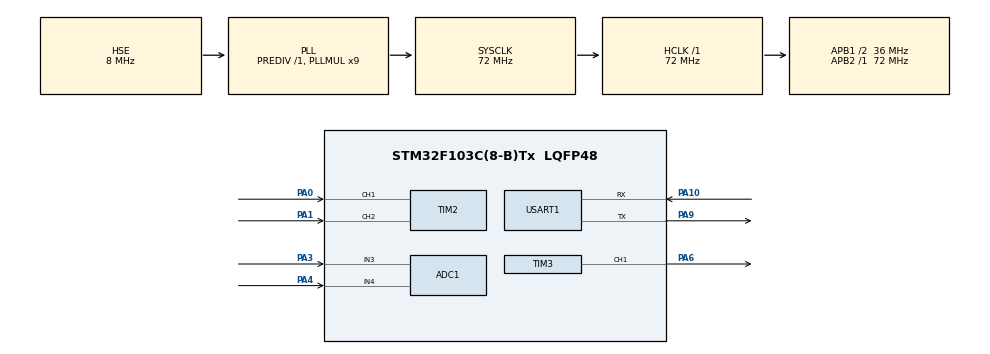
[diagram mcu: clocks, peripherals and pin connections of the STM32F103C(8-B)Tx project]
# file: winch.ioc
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ADC1.Channel-0\#ChannelRegularConversion=ADC_CHANNEL_3
ADC1.Channel-1\#ChannelRegularConversion=ADC_CHANNEL_3
ADC1.ContinuousConvMode=DISABLE
ADC1.DiscontinuousConvMode=ENABLE
ADC1.NbrOfConversion=2
ADC1.NbrOfConversionFlag=1
ADC1.Rank-0\#ChannelRegularConversion=1
ADC1.Rank-1\#ChannelRegularConversion=2
ADC1.SamplingTime-0\#ChannelRegularConversion=ADC_SAMPLETIME_1CYCLE_5
ADC1.SamplingTime-1\#ChannelRegularConversion=ADC_SAMPLETIME_1CYCLE_5
ADC1.master=1
Dma.ADC1.0.Direction=DMA_PERIPH_TO_MEMORY
Dma.ADC1.0.Instance=DMA1_Channel1
Dma.ADC1.0.MemDataAlignment=DMA_MDATAALIGN_WORD
Dma.ADC1.0.MemInc=DMA_MINC_ENABLE
Dma.ADC1.0.Mode=DMA_CIRCULAR
Dma.ADC1.0.PeriphDataAlignment=DMA_PDATAALIGN_WORD
Dma.ADC1.0.PeriphInc=DMA_PINC_DISABLE
Dma.ADC1.0.Priority=DMA_PRIORITY_VERY_HIGH
Dma.Request0=ADC1
Mcu.Family=STM32F1
Mcu.Name=STM32F103C(8-B)Tx
Mcu.Package=LQFP48
NVIC.DMA1_Channel1_IRQn=true\:0\:0\:false\:false\:true\:false\:true
NVIC.PriorityGroup=NVIC_PRIORITYGROUP_4
PA0-WKUP.Signal=S_TIM2_CH1_ETR
PA1.Signal=S_TIM2_CH2
PA10.Mode=Asynchronous
PA10.Signal=USART1_RX
PA13.Mode=Serial_Wire
PA13.Signal=SYS_JTMS-SWDIO
PA14.Mode=Serial_Wire
PA14.Signal=SYS_JTCK-SWCLK
PA3.Signal=ADCx_IN3
PA4.Signal=ADCx_IN4
PA6.Signal=S_TIM3_CH1
PA9.Mode=Asynchronous
PA9.Signal=USART1_TX
PD0-OSC_IN.Mode=HSE-External-Oscillator
PD0-OSC_IN.Signal=RCC_OSC_IN
PD1-OSC_OUT.Mode=HSE-External-Oscillator
PD1-OSC_OUT.Signal=RCC_OSC_OUT
ProjectManager.HeapSize=0x200
ProjectManager.StackSize=0x400
ProjectManager.TargetToolchain=STM32CubeIDE
RCC.ADCPresc=RCC_ADCPCLK2_DIV6
RCC.AHBFreq_Value=72000000
RCC.APB1CLKDivider=RCC_HCLK_DIV2
RCC.APB1Freq_Value=36000000
RCC.APB1TimFreq_Value=72000000
RCC.APB2Freq_Value=72000000
RCC.APB2TimFreq_Value=72000000
RCC.HCLKFreq_Value=72000000
RCC.PLLMUL=RCC_PLL_MUL9
RCC.PLLSourceVirtual=RCC_PLLSOURCE_HSE
RCC.SYSCLKFreq_VALUE=72000000
RCC.SYSCLKSource=RCC_SYSCLKSOURCE_PLLCLK
RCC.USBFreq_Value=72000000
SH.ADCx_IN3.0=ADC1_IN3,IN3
SH.ADCx_IN4.0=ADC1_IN4,IN4
SH.S_TIM2_CH1_ETR.0=TIM2_CH1,Encoder_Interface
SH.S_TIM2_CH2.0=TIM2_CH2,Encoder_Interface
SH.S_TIM3_CH1.0=TIM3_CH1,PWM Generation1 CH1
TIM2.AutoReloadPreload=TIM_AUTORELOAD_PRELOAD_ENABLE
TIM2.EncoderMode=TIM_ENCODERMODE_TI12
TIM2.IC1Filter=10
TIM2.IC2Filter=10
TIM3.AutoReloadPreload=TIM_AUTORELOAD_PRELOAD_ENABLE
TIM3.Channel-PWM\ Generation1\ CH1=TIM_CHANNEL_1
TIM3.OC1Preload_PWM=DISABLE
TIM3.OCFastMode_PWM-PWM\ Generation1\ CH1=TIM_OCFAST_ENABLE
USART1.VirtualMode=VM_ASYNC
VP_TIM3_VS_ClockSourceINT.Mode=Internal
board=custom

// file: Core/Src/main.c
/* USER CODE BEGIN Header */
/**
 ******************************************************************************
 * @file           : main.c
 * @brief          : Main program body
 ******************************************************************************
 * @attention
 *
 * Copyright (c) 2023 STMicroelectronics.
 * All rights reserved.
 *
 * This software is licensed under terms that can be found in the LICENSE file
 * in the root directory of this software component.
 * If no LICENSE file comes with this software, it is provided AS-IS.
 *
 ******************************************************************************
 */
/* USER CODE END Header */
#include "main.h"

/* USER CODE BEGIN Includes */
#define MAX_Tension 300
#define IDEAL_Tension 30
/* USER CODE END Includes */

/* USER CODE BEGIN PTD */
volatile uint32_t tim1_cnt=0,direction,rise=0;

uint32_t adc_val = 0;
uint32_t buffer;
uint8_t MSG[50] = {'\0'};
//float sensitivity = 0.1; // 0.1 for 20A Model
float rawVoltage;
float current;
long val;
/* USER CODE END PTD */

ADC_HandleTypeDef hadc1;
DMA_HandleTypeDef hdma_adc1;

TIM_HandleTypeDef htim2;
TIM_HandleTypeDef htim3;

UART_HandleTypeDef huart1;

void SystemClock_Config(void);
static void MX_GPIO_Init(void);
static void MX_ADC1_Init(void);
static void MX_TIM2_Init(void);
static void MX_DMA_Init(void);
static void MX_USART1_UART_Init(void);
static void MX_TIM3_Init(void);

long map(long x, long in_min, long in_max, long out_min, long out_max)
{
  return (x - in_min) * (out_max - out_min) / (in_max - in_min) + out_min;
}

int main(void)
{

  /* MCU Configuration--------------------------------------------------------*/

  /* Reset of all peripherals, Initializes the Flash interface and the Systick. */
  HAL_Init();

  /* Configure the system clock */
  SystemClock_Config();

  /* Initialize all configured peripherals */
  MX_GPIO_Init();
  MX_ADC1_Init();
  MX_TIM2_Init();
  MX_DMA_Init();
  MX_USART1_UART_Init();
  MX_TIM3_Init();
  /* USER CODE BEGIN 2 */
	HAL_TIM_Encoder_Start(&htim2, TIM_CHANNEL_ALL);
	//HAL_ADC_Start_DMA(&hadc1, &buffer, 1);
	HAL_TIM_PWM_Start(&htim3, TIM_CHANNEL_1);
  /* USER CODE END 2 */

  /* Infinite loop */
  /* USER CODE BEGIN WHILE  ((TIM2->CNT)>>2)*/
	while (1) {
    /* USER CODE END WHILE */
//		tim1_cnt = __HAL_TIM_GET_COUNTER(&htim2);
		HAL_TIM_PeriodElapsedCallback(&htim2);
			direction = !(__HAL_TIM_IS_TIM_COUNTING_DOWN(&htim2));
			sprintf(MSG, "	Ticks = %d, adc=%d ,Current=%f\n", ((TIM2->CNT)>>2),(int)val,current);
			            HAL_UART_Transmit(&huart1, MSG, sizeof(MSG), 10);
			/*if(current>MAX_Tension || current ==0.0)
			{
				while(current > IDEAL_Tension || current==0.0)
				{
					TIM3->CCR1 = 80;

				}
			}*/
	}
}

void HAL_TIM_PeriodElapsedCallback(TIM_HandleTypeDef *htim)

{
	//tim1_cnt = __HAL_TIM_GET_COUNTER(&htim2);

   if (htim -> Instance == TIM2)

   {

   HAL_ADC_Start_DMA(&hadc1, &buffer, 10);

   }

}

void HAL_ADC_ConvCpltCallback(ADC_HandleTypeDef* hadc)
{
   adc_val = buffer;
   val=map(adc_val, 0, 255,0 , 4095);
   rawVoltage = (float) val * 3.3 * 2 / 4095;
       // If rawVoltage is not 2.5Volt, multiply by a factor.In my case it is 1.035
       // This is due to tolerance in voltage divider resister & ADC accuracy
       current =((rawVoltage - 2.503)/0.185)*1000;
   HAL_ADC_Stop_DMA(&hadc1);
}
void SystemClock_Config(void)
{
  RCC_OscInitTypeDef RCC_OscInitStruct = {0};
  RCC_ClkInitTypeDef RCC_ClkInitStruct = {0};
  RCC_PeriphCLKInitTypeDef PeriphClkInit = {0};

  /** Initializes the RCC Oscillators according to the specified parameters
  * in the RCC_OscInitTypeDef structure.
  */
  RCC_OscInitStruct.OscillatorType = RCC_OSCILLATORTYPE_HSE;
  RCC_OscInitStruct.HSEState = RCC_HSE_ON;
  RCC_OscInitStruct.HSEPredivValue = RCC_HSE_PREDIV_DIV1;
  RCC_OscInitStruct.HSIState = RCC_HSI_ON;
  RCC_OscInitStruct.PLL.PLLState = RCC_PLL_ON;
  RCC_OscInitStruct.PLL.PLLSource = RCC_PLLSOURCE_HSE;
  RCC_OscInitStruct.PLL.PLLMUL = RCC_PLL_MUL9;
  if (HAL_RCC_OscConfig(&RCC_OscInitStruct) != HAL_OK)
  {
    Error_Handler();
  }
  /** Initializes the CPU, AHB and APB buses clocks
  */
  RCC_ClkInitStruct.ClockType = RCC_CLOCKTYPE_HCLK|RCC_CLOCKTYPE_SYSCLK
                              |RCC_CLOCKTYPE_PCLK1|RCC_CLOCKTYPE_PCLK2;
  RCC_ClkInitStruct.SYSCLKSource = RCC_SYSCLKSOURCE_PLLCLK;
  RCC_ClkInitStruct.AHBCLKDivider = RCC_SYSCLK_DIV1;
  RCC_ClkInitStruct.APB1CLKDivider = RCC_HCLK_DIV2;
  RCC_ClkInitStruct.APB2CLKDivider = RCC_HCLK_DIV1;

  if (HAL_RCC_ClockConfig(&RCC_ClkInitStruct, FLASH_LATENCY_2) != HAL_OK)
  {
    Error_Handler();
  }
  PeriphClkInit.PeriphClockSelection = RCC_PERIPHCLK_ADC;
  PeriphClkInit.AdcClockSelection = RCC_ADCPCLK2_DIV6;
  if (HAL_RCCEx_PeriphCLKConfig(&PeriphClkInit) != HAL_OK)
  {
    Error_Handler();
  }
}

static void MX_ADC1_Init(void)
{

  ADC_ChannelConfTypeDef sConfig = {0};

  /** Common config
  */
  hadc1.Instance = ADC1;
  hadc1.Init.ScanConvMode = ADC_SCAN_ENABLE;
  hadc1.Init.ContinuousConvMode = DISABLE;
  hadc1.Init.DiscontinuousConvMode = ENABLE;
  hadc1.Init.NbrOfDiscConversion = 1;
  hadc1.Init.ExternalTrigConv = ADC_SOFTWARE_START;
  hadc1.Init.DataAlign = ADC_DATAALIGN_RIGHT;
  hadc1.Init.NbrOfConversion = 2;
  if (HAL_ADC_Init(&hadc1) != HAL_OK)
  {
    Error_Handler();
  }
  /** Configure Regular Channel
  */
  sConfig.Channel = ADC_CHANNEL_3;
  sConfig.Rank = ADC_REGULAR_RANK_1;
  sConfig.SamplingTime = ADC_SAMPLETIME_1CYCLE_5;
  if (HAL_ADC_ConfigChannel(&hadc1, &sConfig) != HAL_OK)
  {
    Error_Handler();
  }
  /** Configure Regular Channel
  */
  sConfig.Rank = ADC_REGULAR_RANK_2;
  if (HAL_ADC_ConfigChannel(&hadc1, &sConfig) != HAL_OK)
  {
    Error_Handler();
  }

}

static void MX_TIM2_Init(void)
{

  TIM_Encoder_InitTypeDef sConfig = {0};
  TIM_MasterConfigTypeDef sMasterConfig = {0};

  htim2.Instance = TIM2;
  htim2.Init.Prescaler = 0;
  htim2.Init.CounterMode = TIM_COUNTERMODE_UP;
  htim2.Init.Period = 65535;
  htim2.Init.ClockDivision = TIM_CLOCKDIVISION_DIV1;
  htim2.Init.AutoReloadPreload = TIM_AUTORELOAD_PRELOAD_ENABLE;
  sConfig.EncoderMode = TIM_ENCODERMODE_TI12;
  sConfig.IC1Polarity = TIM_ICPOLARITY_RISING;
  sConfig.IC1Selection = TIM_ICSELECTION_DIRECTTI;
  sConfig.IC1Prescaler = TIM_ICPSC_DIV1;
  sConfig.IC1Filter = 10;
  sConfig.IC2Polarity = TIM_ICPOLARITY_RISING;
  sConfig.IC2Selection = TIM_ICSELECTION_DIRECTTI;
  sConfig.IC2Prescaler = TIM_ICPSC_DIV1;
  sConfig.IC2Filter = 10;
  if (HAL_TIM_Encoder_Init(&htim2, &sConfig) != HAL_OK)
  {
    Error_Handler();
  }
  sMasterConfig.MasterOutputTrigger = TIM_TRGO_RESET;
  sMasterConfig.MasterSlaveMode = TIM_MASTERSLAVEMODE_DISABLE;
  if (HAL_TIMEx_MasterConfigSynchronization(&htim2, &sMasterConfig) != HAL_OK)
  {
    Error_Handler();
  }

}

static void MX_TIM3_Init(void)
{

  TIM_ClockConfigTypeDef sClockSourceConfig = {0};
  TIM_MasterConfigTypeDef sMasterConfig = {0};
  TIM_OC_InitTypeDef sConfigOC = {0};

  htim3.Instance = TIM3;
  htim3.Init.Prescaler = 0;
  htim3.Init.CounterMode = TIM_COUNTERMODE_UP;
  htim3.Init.Period = 65535;
  htim3.Init.ClockDivision = TIM_CLOCKDIVISION_DIV1;
  htim3.Init.AutoReloadPreload = TIM_AUTORELOAD_PRELOAD_ENABLE;
  if (HAL_TIM_Base_Init(&htim3) != HAL_OK)
  {
    Error_Handler();
  }
  sClockSourceConfig.ClockSource = TIM_CLOCKSOURCE_INTERNAL;
  if (HAL_TIM_ConfigClockSource(&htim3, &sClockSourceConfig) != HAL_OK)
  {
    Error_Handler();
  }
  if (HAL_TIM_PWM_Init(&htim3) != HAL_OK)
  {
    Error_Handler();
  }
  sMasterConfig.MasterOutputTrigger = TIM_TRGO_RESET;
  sMasterConfig.MasterSlaveMode = TIM_MASTERSLAVEMODE_DISABLE;
  if (HAL_TIMEx_MasterConfigSynchronization(&htim3, &sMasterConfig) != HAL_OK)
  {
    Error_Handler();
  }
  sConfigOC.OCMode = TIM_OCMODE_PWM1;
  sConfigOC.Pulse = 0;
  sConfigOC.OCPolarity = TIM_OCPOLARITY_HIGH;
  sConfigOC.OCFastMode = TIM_OCFAST_DISABLE;
  if (HAL_TIM_PWM_ConfigChannel(&htim3, &sConfigOC, TIM_CHANNEL_1) != HAL_OK)
  {
    Error_Handler();
  }
  HAL_TIM_MspPostInit(&htim3);

}

static void MX_USART1_UART_Init(void)
{

  huart1.Instance = USART1;
  huart1.Init.BaudRate = 115200;
  huart1.Init.WordLength = UART_WORDLENGTH_8B;
  huart1.Init.StopBits = UART_STOPBITS_1;
  huart1.Init.Parity = UART_PARITY_NONE;
  huart1.Init.Mode = UART_MODE_TX_RX;
  huart1.Init.HwFlowCtl = UART_HWCONTROL_NONE;
  huart1.Init.OverSampling = UART_OVERSAMPLING_16;
  if (HAL_UART_Init(&huart1) != HAL_OK)
  {
    Error_Handler();
  }

}

static void MX_DMA_Init(void)
{

  /* DMA controller clock enable */
  __HAL_RCC_DMA1_CLK_ENABLE();

  /* DMA interrupt init */
  /* DMA1_Channel1_IRQn interrupt configuration */
  HAL_NVIC_SetPriority(DMA1_Channel1_IRQn, 0, 0);
  HAL_NVIC_EnableIRQ(DMA1_Channel1_IRQn);

}

static void MX_GPIO_Init(void)
{

  /* GPIO Ports Clock Enable */
  __HAL_RCC_GPIOD_CLK_ENABLE();
  __HAL_RCC_GPIOA_CLK_ENABLE();

}

void Error_Handler(void)
{
	__disable_irq();
	while (1) {
	}
}
